AUTOSAR XML (schema 4-2-2)
package /STELLANTIS/EPT/ASWCs
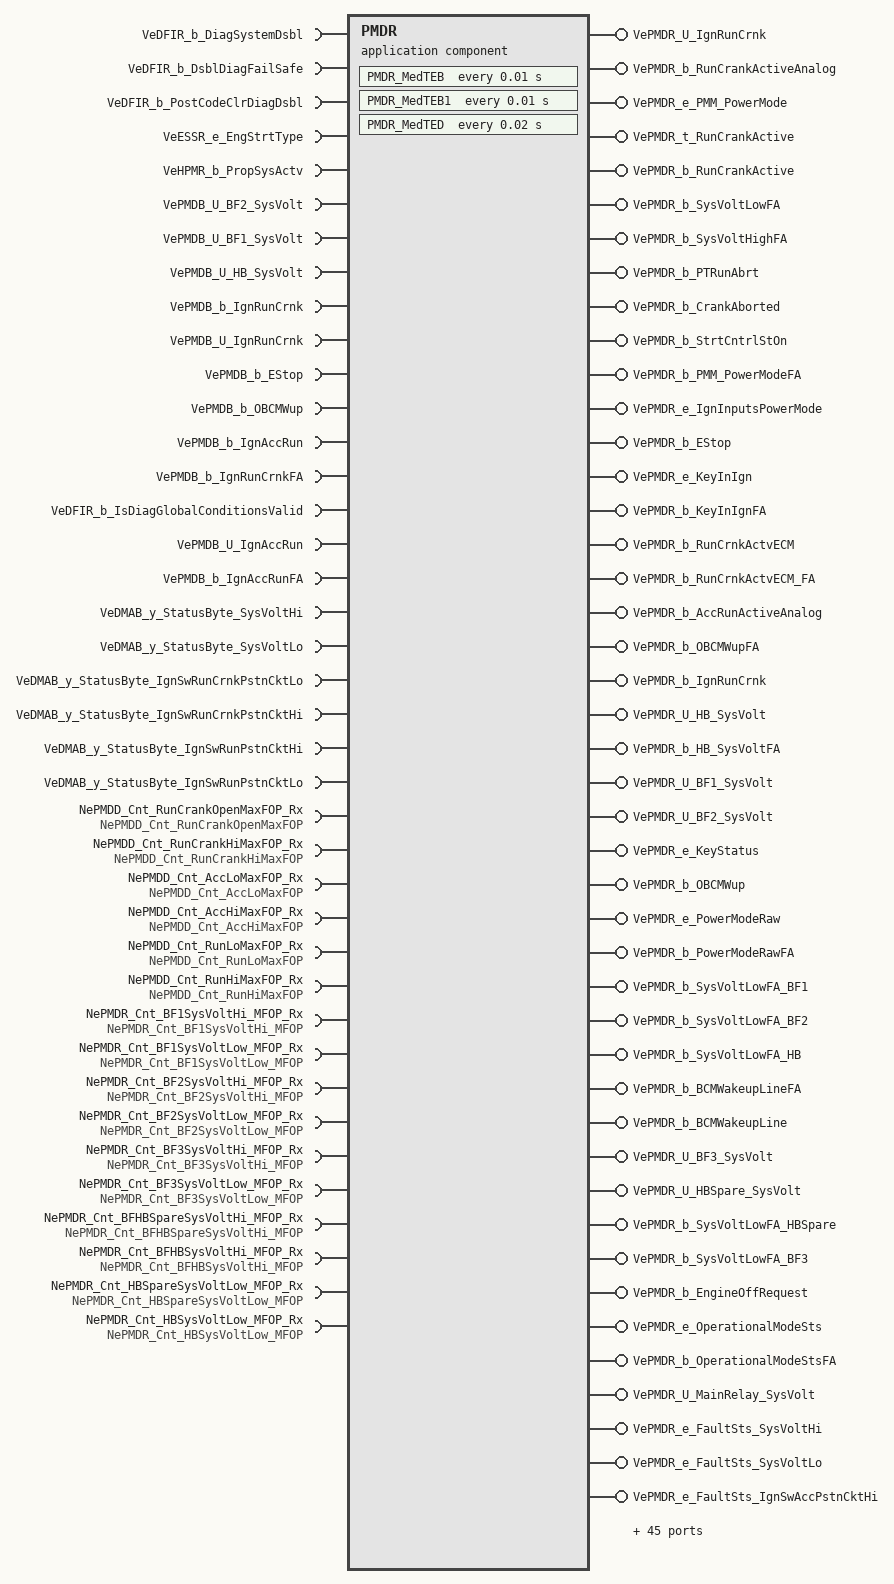
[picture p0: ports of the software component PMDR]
  application sw component type PMDR
    23 x require port:
      VeDFIR_b_DiagSystemDsbl: nonqueued-receiver-com-spec{data-element=Value, init-value=0}, required-interface=VeDFIR_b_DiagSystemDsbl
      VeDFIR_b_DsblDiagFailSafe: variation-point={short-label=vpVeDFIR_b_DsblDiagFailSafe, sw-syscond=1}, nonqueued-receiver-com-spec{data-element=Value, init-value=0}, required-interface=VeDFIR_b_DsblDiagFailSafe
      VeDFIR_b_PostCodeClrDiagDsbl: variation-point={short-label=vpVeDFIR_b_PostCodeClrDiagDsbl, sw-syscond=1}, nonqueued-receiver-com-spec{data-element=Value, init-value=0}, required-interface=VeDFIR_b_PostCodeClrDiagDsbl
      VeESSR_e_EngStrtType: nonqueued-receiver-com-spec{data-element=Value, init-value=CeESSR_e_NoStrt}, required-interface=VeESSR_e_EngStrtType
      VeHPMR_b_PropSysActv: variation-point={short-label=vpVeHPMR_b_PropSysActv, sw-syscond=1}, nonqueued-receiver-com-spec{data-element=Value, init-value=0}, required-interface=VeHPMR_b_PropSysActv
      VePMDB_U_BF2_SysVolt: nonqueued-receiver-com-spec{data-element=Value, init-value=0}, required-interface=VePMDB_U_BF2_SysVolt
      VePMDB_U_BF1_SysVolt: nonqueued-receiver-com-spec{data-element=Value, init-value=0}, required-interface=VePMDB_U_BF1_SysVolt
      VePMDB_U_HB_SysVolt: nonqueued-receiver-com-spec{data-element=Value, init-value=0}, required-interface=VePMDB_U_HB_SysVolt
      VePMDB_b_IgnRunCrnk: nonqueued-receiver-com-spec{data-element=Value, init-value=0}, required-interface=VePMDB_b_IgnRunCrnk
      VePMDB_U_IgnRunCrnk: nonqueued-receiver-com-spec{data-element=Value, init-value=0}, required-interface=VePMDB_U_IgnRunCrnk
      VePMDB_b_EStop: nonqueued-receiver-com-spec{data-element=Value, init-value=0}, required-interface=VePMDB_b_EStop
      VePMDB_b_OBCMWup: nonqueued-receiver-com-spec{data-element=Value, init-value=0}, required-interface=VePMDB_b_OBCMWup
      VePMDB_b_IgnAccRun: nonqueued-receiver-com-spec{data-element=Value, init-value=0}, required-interface=VePMDB_b_IgnAccRun
      VePMDB_b_IgnRunCrnkFA: nonqueued-receiver-com-spec{data-element=Value, init-value=0}, required-interface=VePMDB_b_IgnRunCrnkFA
      VeDFIR_b_IsDiagGlobalConditionsValid: variation-point={short-label=vpVeDFIR_b_IsDiagGlobalConditionsValid, sw-syscond=1}, nonqueued-receiver-com-spec{data-element=Value, init-value=0}, required-interface=VeDFIR_b_IsDiagGlobalConditionsValid
      VePMDB_U_IgnAccRun: nonqueued-receiver-com-spec{data-element=Value, init-value=0}, required-interface=VePMDB_U_IgnAccRun
      VePMDB_b_IgnAccRunFA: nonqueued-receiver-com-spec{data-element=Value, init-value=0}, required-interface=VePMDB_b_IgnAccRunFA
      VeDMAB_y_StatusByte_SysVoltHi: variation-point={short-label=vpVeDMAB_y_StatusByte_SysVoltHi, sw-syscond=1}, nonqueued-receiver-com-spec{data-element=Value, init-value=0}, required-interface=VeDMAB_y_StatusByte_SysVoltHi
      VeDMAB_y_StatusByte_SysVoltLo: variation-point={short-label=vpVeDMAB_y_StatusByte_SysVoltLo, sw-syscond=1}, nonqueued-receiver-com-spec{data-element=Value, init-value=0}, required-interface=VeDMAB_y_StatusByte_SysVoltLo
      VeDMAB_y_StatusByte_IgnSwRunCrnkPstnCktLo: variation-point={short-label=vpVeDMAB_y_StatusByte_IgnSwRunCrnkPstnCktLo, sw-syscond=1}, nonqueued-receiver-com-spec{data-element=Value, init-value=0}, required-interface=VeDMAB_y_StatusByte_IgnSwRunCrnkPstnCktLo
      VeDMAB_y_StatusByte_IgnSwRunCrnkPstnCktHi: variation-point={short-label=vpVeDMAB_y_StatusByte_IgnSwRunCrnkPstnCktHi, sw-syscond=1}, nonqueued-receiver-com-spec{data-element=Value, init-value=0}, required-interface=VeDMAB_y_StatusByte_IgnSwRunCrnkPstnCktHi
      VeDMAB_y_StatusByte_IgnSwRunPstnCktHi: variation-point={short-label=vpVeDMAB_y_StatusByte_IgnSwRunPstnCktHi, sw-syscond=1}, nonqueued-receiver-com-spec{data-element=Value, init-value=0}, required-interface=VeDMAB_y_StatusByte_IgnSwRunPstnCktHi
      VeDMAB_y_StatusByte_IgnSwRunPstnCktLo: variation-point={short-label=vpVeDMAB_y_StatusByte_IgnSwRunPstnCktLo, sw-syscond=1}, nonqueued-receiver-com-spec{data-element=Value, init-value=0}, required-interface=VeDMAB_y_StatusByte_IgnSwRunPstnCktLo
    73 x provide port:
      VePMDR_U_IgnRunCrnk: nonqueued-sender-com-spec{data-element=Value, init-value=0}, provided-interface=VePMDR_U_IgnRunCrnk
      VePMDR_b_RunCrankActiveAnalog: nonqueued-sender-com-spec{data-element=Value, init-value=0}, provided-interface=VePMDR_b_RunCrankActiveAnalog
      VePMDR_e_PMM_PowerMode: nonqueued-sender-com-spec{data-element=Value, init-value=CePMDR_e_PowerMode_Off}, provided-interface=VePMDR_e_PMM_PowerMode
      VePMDR_t_RunCrankActive: nonqueued-sender-com-spec{data-element=Value, init-value=0}, provided-interface=VePMDR_t_RunCrankActive
      VePMDR_b_RunCrankActive: nonqueued-sender-com-spec{data-element=Value, init-value=0}, provided-interface=VePMDR_b_RunCrankActive
      VePMDR_b_SysVoltLowFA: nonqueued-sender-com-spec{data-element=Value, init-value=0}, provided-interface=VePMDR_b_SysVoltLowFA
      VePMDR_b_SysVoltHighFA: nonqueued-sender-com-spec{data-element=Value, init-value=0}, provided-interface=VePMDR_b_SysVoltHighFA
      VePMDR_b_PTRunAbrt: nonqueued-sender-com-spec{data-element=Value, init-value=0}, provided-interface=VePMDR_b_PTRunAbrt
      VePMDR_b_CrankAborted: nonqueued-sender-com-spec{data-element=Value, init-value=0}, provided-interface=VePMDR_b_CrankAborted
      VePMDR_b_StrtCntrlStOn: nonqueued-sender-com-spec{data-element=Value, init-value=0}, provided-interface=VePMDR_b_StrtCntrlStOn
      VePMDR_b_PMM_PowerModeFA: nonqueued-sender-com-spec{data-element=Value, init-value=0}, provided-interface=VePMDR_b_PMM_PowerModeFA
      VePMDR_e_IgnInputsPowerMode: nonqueued-sender-com-spec{data-element=Value, init-value=CePMDR_e_PowerMode_Off}, provided-interface=VePMDR_e_IgnInputsPowerMode
      VePMDR_b_EStop: nonqueued-sender-com-spec{data-element=Value, init-value=0}, provided-interface=VePMDR_b_EStop
      VePMDR_e_KeyInIgn: nonqueued-sender-com-spec{data-element=Value, init-value=CePMDR_e_KeyInIgn_DEFAULT}, provided-interface=VePMDR_e_KeyInIgn
      VePMDR_b_KeyInIgnFA: nonqueued-sender-com-spec{data-element=Value, init-value=0}, provided-interface=VePMDR_b_KeyInIgnFA
      VePMDR_b_RunCrnkActvECM: nonqueued-sender-com-spec{data-element=Value, init-value=0}, provided-interface=VePMDR_b_RunCrnkActvECM
      VePMDR_b_RunCrnkActvECM_FA: nonqueued-sender-com-spec{data-element=Value, init-value=0}, provided-interface=VePMDR_b_RunCrnkActvECM_FA
      VePMDR_b_AccRunActiveAnalog: nonqueued-sender-com-spec{data-element=Value, init-value=0}, provided-interface=VePMDR_b_AccRunActiveAnalog
      VePMDR_b_OBCMWupFA: nonqueued-sender-com-spec{data-element=Value, init-value=0}, provided-interface=VePMDR_b_OBCMWupFA
      VePMDR_b_IgnRunCrnk: nonqueued-sender-com-spec{data-element=Value, init-value=0}, provided-interface=VePMDR_b_IgnRunCrnk
      VePMDR_U_HB_SysVolt: nonqueued-sender-com-spec{data-element=Value, init-value=0}, provided-interface=VePMDR_U_HB_SysVolt
      VePMDR_b_HB_SysVoltFA: nonqueued-sender-com-spec{data-element=Value, init-value=0}, provided-interface=VePMDR_b_HB_SysVoltFA
      VePMDR_U_BF1_SysVolt: nonqueued-sender-com-spec{data-element=Value, init-value=0}, provided-interface=VePMDR_U_BF1_SysVolt
      VePMDR_U_BF2_SysVolt: nonqueued-sender-com-spec{data-element=Value, init-value=0}, provided-interface=VePMDR_U_BF2_SysVolt
      VePMDR_e_KeyStatus: nonqueued-sender-com-spec{data-element=Value, init-value=CePMDR_e_KeySt_Off}, provided-interface=VePMDR_e_KeyStatus
      VePMDR_b_OBCMWup: nonqueued-sender-com-spec{data-element=Value, init-value=0}, provided-interface=VePMDR_b_OBCMWup
      VePMDR_e_PowerModeRaw: nonqueued-sender-com-spec{data-element=Value, init-value=CePMDR_e_PowerMode_Off}, provided-interface=VePMDR_e_PowerModeRaw
      VePMDR_b_PowerModeRawFA: nonqueued-sender-com-spec{data-element=Value, init-value=0}, provided-interface=VePMDR_b_PowerModeRawFA
      VePMDR_b_SysVoltLowFA_BF1: nonqueued-sender-com-spec{data-element=Value, init-value=0}, provided-interface=VePMDR_b_SysVoltLowFA_BF1
      VePMDR_b_SysVoltLowFA_BF2: nonqueued-sender-com-spec{data-element=Value, init-value=0}, provided-interface=VePMDR_b_SysVoltLowFA_BF2
      VePMDR_b_SysVoltLowFA_HB: nonqueued-sender-com-spec{data-element=Value, init-value=0}, provided-interface=VePMDR_b_SysVoltLowFA_HB
      VePMDR_b_BCMWakeupLineFA: nonqueued-sender-com-spec{data-element=Value, init-value=0}, provided-interface=VePMDR_b_BCMWakeupLineFA
      VePMDR_b_BCMWakeupLine: nonqueued-sender-com-spec{data-element=Value, init-value=0}, provided-interface=VePMDR_b_BCMWakeupLine
      VePMDR_U_BF3_SysVolt: nonqueued-sender-com-spec{data-element=Value, init-value=0}, provided-interface=VePMDR_U_BF3_SysVolt
      VePMDR_U_HBSpare_SysVolt: nonqueued-sender-com-spec{data-element=Value, init-value=0}, provided-interface=VePMDR_U_HBSpare_SysVolt
      VePMDR_b_SysVoltLowFA_HBSpare: nonqueued-sender-com-spec{data-element=Value, init-value=0}, provided-interface=VePMDR_b_SysVoltLowFA_HBSpare
      VePMDR_b_SysVoltLowFA_BF3: nonqueued-sender-com-spec{data-element=Value, init-value=0}, provided-interface=VePMDR_b_SysVoltLowFA_BF3
      VePMDR_b_EngineOffRequest: nonqueued-sender-com-spec{data-element=Value, init-value=0}, provided-interface=VePMDR_b_EngineOffRequest
      VePMDR_e_OperationalModeSts: nonqueued-sender-com-spec{data-element=Value, init-value=CePMDR_e_Init}, provided-interface=VePMDR_e_OperationalModeSts
      VePMDR_b_OperationalModeStsFA: nonqueued-sender-com-spec{data-element=Value, init-value=0}, provided-interface=VePMDR_b_OperationalModeStsFA
      VePMDR_U_MainRelay_SysVolt: nonqueued-sender-com-spec{data-element=Value, init-value=0}, provided-interface=VePMDR_U_MainRelay_SysVolt
      VePMDR_e_FaultSts_SysVoltHi: nonqueued-sender-com-spec{data-element=Value, init-value=CeDFIB_e_Init}, provided-interface=VePMDR_e_FaultSts_SysVoltHi
      VePMDR_e_FaultSts_SysVoltLo: nonqueued-sender-com-spec{data-element=Value, init-value=CeDFIB_e_Init}, provided-interface=VePMDR_e_FaultSts_SysVoltLo
      VePMDR_e_FaultSts_IgnSwAccPstnCktHi: nonqueued-sender-com-spec{data-element=Value, init-value=CeDFIB_e_Init}, provided-interface=VePMDR_e_FaultSts_IgnSwAccPstnCktHi
      VePMDR_e_FaultSts_IgnSwAccPstnCktLo: nonqueued-sender-com-spec{data-element=Value, init-value=CeDFIB_e_Init}, provided-interface=VePMDR_e_FaultSts_IgnSwAccPstnCktLo
      VePMDR_e_FaultSts_IgnSwRunCrnkPstnCktLo: nonqueued-sender-com-spec{data-element=Value, init-value=CeDFIB_e_Init}, provided-interface=VePMDR_e_FaultSts_IgnSwRunCrnkPstnCktLo
      VePMDR_e_FaultSts_IgnSwRunCrnkPstnCktHi: nonqueued-sender-com-spec{data-element=Value, init-value=CeDFIB_e_Init}, provided-interface=VePMDR_e_FaultSts_IgnSwRunCrnkPstnCktHi
      VePMDR_e_FaultSts_IgnSwRunPstnCktHi: nonqueued-sender-com-spec{data-element=Value, init-value=CeDFIB_e_Init}, provided-interface=VePMDR_e_FaultSts_IgnSwRunPstnCktHi
      VePMDR_e_FaultSts_IgnSwRunPstnCktLo: nonqueued-sender-com-spec{data-element=Value, init-value=CeDFIB_e_Init}, provided-interface=VePMDR_e_FaultSts_IgnSwRunPstnCktLo
      FsftPMDR_b_EngOffRq_C: server-com-spec=FsftPMDR_b_EngOffRq_C, provided-interface=FsftPMDR_b_EngOffRq_C
      FsftPMDR_b_EngOffRq_C2: server-com-spec=FsftPMDR_b_EngOffRq_C2, provided-interface=FsftPMDR_b_EngOffRq_C2
      FsftPMDR_b_OperationalModeSts: server-com-spec=FsftPMDR_b_OperationalModeSts, provided-interface=FsftPMDR_b_OperationalModeSts
      FsftPMDR_b_PAD_Actv: server-com-spec=FsftPMDR_b_PAD_Actv, provided-interface=FsftPMDR_b_PAD_Actv
      FsftPMDR_b_RunCrnkActvECM: server-com-spec=FsftPMDR_b_RunCrnkActvECM, provided-interface=FsftPMDR_b_RunCrnkActvECM
      FsftPMDR_b_StrtCntrlStOn: server-com-spec=FsftPMDR_b_StrtCntrlStOn, provided-interface=FsftPMDR_b_StrtCntrlStOn
      FsftPMDR_e_KeyInIgn: server-com-spec=FsftPMDR_e_KeyInIgn, provided-interface=FsftPMDR_e_KeyInIgn
      FsftPMDR_e_PowerModeRaw: server-com-spec=FsftPMDR_e_PowerModeRaw, provided-interface=FsftPMDR_e_PowerModeRaw
      FsftPMDR_e_Tonale_PowerModeRaw: server-com-spec=FsftPMDR_e_Tonale_PowerModeRaw, provided-interface=FsftPMDR_e_Tonale_PowerModeRaw
      PokePMDR_U_BF3_SysVolt: server-com-spec{operation=PokePMDR_U_BF3_SysVolt, queue-length=1}, provided-interface=PokePMDR_U_BF3_SysVolt
      PokePMDR_U_HBSpare_SysVolt: server-com-spec{operation=PokePMDR_U_HBSpare_SysVolt, queue-length=1}, provided-interface=PokePMDR_U_HBSpare_SysVolt
      PokePMDR_U_MainRelay_SysVolt: server-com-spec{operation=PokePMDR_U_MainRelay_SysVolt, queue-length=1}, provided-interface=PokePMDR_U_MainRelay_SysVolt
      PokePMDR_b_BCMWup: server-com-spec{operation=PokePMDR_b_BCMWup, queue-length=1}, provided-interface=PokePMDR_b_BCMWup
      PokePMDR_b_CrankAborted: server-com-spec{operation=PokePMDR_b_CrankAborted, queue-length=1}, provided-interface=PokePMDR_b_CrankAborted
      PokePMDR_b_EngOffRq_C: server-com-spec{operation=PokePMDR_b_EngOffRq_C, queue-length=1}, provided-interface=PokePMDR_b_EngOffRq_C
      PokePMDR_b_EngOffRq_C2: server-com-spec{operation=PokePMDR_b_EngOffRq_C2, queue-length=1}, provided-interface=PokePMDR_b_EngOffRq_C2
      PokePMDR_b_PAD_Actv: server-com-spec{operation=PokePMDR_b_PAD_Actv, queue-length=1}, provided-interface=PokePMDR_b_PAD_Actv
      PokePMDR_b_PTRunAbrt: server-com-spec{operation=PokePMDR_b_PTRunAbrt, queue-length=1}, provided-interface=PokePMDR_b_PTRunAbrt
      PokePMDR_b_RunCrnkActvECM: server-com-spec{operation=PokePMDR_b_RunCrnkActvECM, queue-length=1}, provided-interface=PokePMDR_b_RunCrnkActvECM
      PokePMDR_b_StrtCntrlStOn: server-com-spec{operation=PokePMDR_b_StrtCntrlStOn, queue-length=1}, provided-interface=PokePMDR_b_StrtCntrlStOn
      PokePMDR_e_KeyInIgn: server-com-spec{operation=PokePMDR_e_KeyInIgn, queue-length=1}, provided-interface=PokePMDR_e_KeyInIgn
      PokePMDR_e_OperationalModeSts: server-com-spec{operation=PokePMDR_e_OperationalModeSts, queue-length=1}, provided-interface=PokePMDR_e_OperationalModeSts
      PokePMDR_e_PowerModeRaw: server-com-spec{operation=PokePMDR_e_PowerModeRaw, queue-length=1}, provided-interface=PokePMDR_e_PowerModeRaw
      PokePMDR_e_Tonale_PowerModeRaw: server-com-spec{operation=PokePMDR_e_Tonale_PowerModeRaw, queue-length=1}, provided-interface=PokePMDR_e_Tonale_PowerModeRaw
    16 x require port:
      NePMDD_Cnt_RunCrankOpenMaxFOP_Rx: nv-require-com-spec{init-value=0, variable=NePMDD_Cnt_RunCrankOpenMaxFOP}, required-interface=NePMDD_Cnt_RunCrankOpenMaxFOP
      NePMDD_Cnt_RunCrankHiMaxFOP_Rx: nv-require-com-spec{init-value=0, variable=NePMDD_Cnt_RunCrankHiMaxFOP}, required-interface=NePMDD_Cnt_RunCrankHiMaxFOP
      NePMDD_Cnt_AccLoMaxFOP_Rx: nv-require-com-spec{init-value=0, variable=NePMDD_Cnt_AccLoMaxFOP}, required-interface=NePMDD_Cnt_AccLoMaxFOP
      NePMDD_Cnt_AccHiMaxFOP_Rx: nv-require-com-spec{init-value=0, variable=NePMDD_Cnt_AccHiMaxFOP}, required-interface=NePMDD_Cnt_AccHiMaxFOP
      NePMDD_Cnt_RunLoMaxFOP_Rx: nv-require-com-spec{init-value=0, variable=NePMDD_Cnt_RunLoMaxFOP}, required-interface=NePMDD_Cnt_RunLoMaxFOP
      NePMDD_Cnt_RunHiMaxFOP_Rx: nv-require-com-spec{init-value=0, variable=NePMDD_Cnt_RunHiMaxFOP}, required-interface=NePMDD_Cnt_RunHiMaxFOP
      NePMDR_Cnt_BF1SysVoltHi_MFOP_Rx: nv-require-com-spec{init-value=0, variable=NePMDR_Cnt_BF1SysVoltHi_MFOP}, required-interface=NePMDR_Cnt_BF1SysVoltHi_MFOP
      NePMDR_Cnt_BF1SysVoltLow_MFOP_Rx: nv-require-com-spec{init-value=0, variable=NePMDR_Cnt_BF1SysVoltLow_MFOP}, required-interface=NePMDR_Cnt_BF1SysVoltLow_MFOP
      NePMDR_Cnt_BF2SysVoltHi_MFOP_Rx: nv-require-com-spec{init-value=0, variable=NePMDR_Cnt_BF2SysVoltHi_MFOP}, required-interface=NePMDR_Cnt_BF2SysVoltHi_MFOP
      NePMDR_Cnt_BF2SysVoltLow_MFOP_Rx: nv-require-com-spec{init-value=0, variable=NePMDR_Cnt_BF2SysVoltLow_MFOP}, required-interface=NePMDR_Cnt_BF2SysVoltLow_MFOP
      NePMDR_Cnt_BF3SysVoltHi_MFOP_Rx: nv-require-com-spec{init-value=0, variable=NePMDR_Cnt_BF3SysVoltHi_MFOP}, required-interface=NePMDR_Cnt_BF3SysVoltHi_MFOP
      NePMDR_Cnt_BF3SysVoltLow_MFOP_Rx: nv-require-com-spec{init-value=0, variable=NePMDR_Cnt_BF3SysVoltLow_MFOP}, required-interface=NePMDR_Cnt_BF3SysVoltLow_MFOP
      NePMDR_Cnt_BFHBSpareSysVoltHi_MFOP_Rx: nv-require-com-spec{init-value=0, variable=NePMDR_Cnt_BFHBSpareSysVoltHi_MFOP}, required-interface=NePMDR_Cnt_BFHBSpareSysVoltHi_MFOP
      NePMDR_Cnt_BFHBSysVoltHi_MFOP_Rx: nv-require-com-spec{init-value=0, variable=NePMDR_Cnt_BFHBSysVoltHi_MFOP}, required-interface=NePMDR_Cnt_BFHBSysVoltHi_MFOP
      NePMDR_Cnt_HBSpareSysVoltLow_MFOP_Rx: nv-require-com-spec{init-value=0, variable=NePMDR_Cnt_HBSpareSysVoltLow_MFOP}, required-interface=NePMDR_Cnt_HBSpareSysVoltLow_MFOP
      NePMDR_Cnt_HBSysVoltLow_MFOP_Rx: nv-require-com-spec{init-value=0, variable=NePMDR_Cnt_HBSysVoltLow_MFOP}, required-interface=NePMDR_Cnt_HBSysVoltLow_MFOP
    16 x provide port:
      NePMDD_Cnt_RunCrankOpenMaxFOP: nv-provide-com-spec{ram-block-init-value=0, variable=NePMDD_Cnt_RunCrankOpenMaxFOP}, provided-interface=NePMDD_Cnt_RunCrankOpenMaxFOP
      NePMDD_Cnt_RunCrankHiMaxFOP: nv-provide-com-spec{ram-block-init-value=0, variable=NePMDD_Cnt_RunCrankHiMaxFOP}, provided-interface=NePMDD_Cnt_RunCrankHiMaxFOP
      NePMDD_Cnt_AccLoMaxFOP: nv-provide-com-spec{ram-block-init-value=0, variable=NePMDD_Cnt_AccLoMaxFOP}, provided-interface=NePMDD_Cnt_AccLoMaxFOP
      NePMDD_Cnt_AccHiMaxFOP: nv-provide-com-spec{ram-block-init-value=0, variable=NePMDD_Cnt_AccHiMaxFOP}, provided-interface=NePMDD_Cnt_AccHiMaxFOP
      NePMDD_Cnt_RunLoMaxFOP: nv-provide-com-spec{ram-block-init-value=0, variable=NePMDD_Cnt_RunLoMaxFOP}, provided-interface=NePMDD_Cnt_RunLoMaxFOP
      NePMDD_Cnt_RunHiMaxFOP: nv-provide-com-spec{ram-block-init-value=0, variable=NePMDD_Cnt_RunHiMaxFOP}, provided-interface=NePMDD_Cnt_RunHiMaxFOP
      NePMDR_Cnt_BF1SysVoltHi_MFOP: nv-provide-com-spec{ram-block-init-value=0, variable=NePMDR_Cnt_BF1SysVoltHi_MFOP}, provided-interface=NePMDR_Cnt_BF1SysVoltHi_MFOP
      NePMDR_Cnt_BF1SysVoltLow_MFOP: nv-provide-com-spec{ram-block-init-value=0, variable=NePMDR_Cnt_BF1SysVoltLow_MFOP}, provided-interface=NePMDR_Cnt_BF1SysVoltLow_MFOP
      NePMDR_Cnt_BF2SysVoltHi_MFOP: nv-provide-com-spec{ram-block-init-value=0, variable=NePMDR_Cnt_BF2SysVoltHi_MFOP}, provided-interface=NePMDR_Cnt_BF2SysVoltHi_MFOP
      NePMDR_Cnt_BF2SysVoltLow_MFOP: nv-provide-com-spec{ram-block-init-value=0, variable=NePMDR_Cnt_BF2SysVoltLow_MFOP}, provided-interface=NePMDR_Cnt_BF2SysVoltLow_MFOP
      NePMDR_Cnt_BF3SysVoltHi_MFOP: nv-provide-com-spec{ram-block-init-value=0, variable=NePMDR_Cnt_BF3SysVoltHi_MFOP}, provided-interface=NePMDR_Cnt_BF3SysVoltHi_MFOP
      NePMDR_Cnt_BF3SysVoltLow_MFOP: nv-provide-com-spec{ram-block-init-value=0, variable=NePMDR_Cnt_BF3SysVoltLow_MFOP}, provided-interface=NePMDR_Cnt_BF3SysVoltLow_MFOP
      NePMDR_Cnt_BFHBSpareSysVoltHi_MFOP: nv-provide-com-spec{ram-block-init-value=0, variable=NePMDR_Cnt_BFHBSpareSysVoltHi_MFOP}, provided-interface=NePMDR_Cnt_BFHBSpareSysVoltHi_MFOP
      NePMDR_Cnt_BFHBSysVoltHi_MFOP: nv-provide-com-spec{ram-block-init-value=0, variable=NePMDR_Cnt_BFHBSysVoltHi_MFOP}, provided-interface=NePMDR_Cnt_BFHBSysVoltHi_MFOP
      NePMDR_Cnt_HBSpareSysVoltLow_MFOP: nv-provide-com-spec{ram-block-init-value=0, variable=NePMDR_Cnt_HBSpareSysVoltLow_MFOP}, provided-interface=NePMDR_Cnt_HBSpareSysVoltLow_MFOP
      NePMDR_Cnt_HBSysVoltLow_MFOP: nv-provide-com-spec{ram-block-init-value=0, variable=NePMDR_Cnt_HBSysVoltLow_MFOP}, provided-interface=NePMDR_Cnt_HBSysVoltLow_MFOP
    behavior IB_PMDR: data-type-mapping=msADTtoIDTMapping, handle-termination-and-restart=NO-SUPPORT, included-data-type-set=data-type=[TePMDR_e_AccRunSrc, TePMDR_e_PMM_PowerModeSrc, TePMDR_e_RunCrankSrc]
      timing event Event_MedTEB: start-on-event=PMDR_MedTEB, period=0.01
      timing event Event_MedTEB1: start-on-event=PMDR_MedTEB1, period=0.01
      timing event Event_MedTED: start-on-event=PMDR_MedTED, period=0.02
      24 x operation invoked event:
        Event_FsftPMDR_b_EngOffRq_C: start-on-event=FsftPMDR_b_EngOffRq_C, operation=FsftPMDR_b_EngOffRq_C.FsftPMDR_b_EngOffRq_C
        Event_FsftPMDR_b_EngOffRq_C2: start-on-event=FsftPMDR_b_EngOffRq_C2, operation=FsftPMDR_b_EngOffRq_C2.FsftPMDR_b_EngOffRq_C2
        Event_FsftPMDR_b_OperationalModeSts: start-on-event=FsftPMDR_b_OperationalModeSts, operation=FsftPMDR_b_OperationalModeSts.FsftPMDR_b_OperationalModeSts
        Event_FsftPMDR_b_PAD_Actv: start-on-event=FsftPMDR_b_PAD_Actv, operation=FsftPMDR_b_PAD_Actv.FsftPMDR_b_PAD_Actv
        Event_FsftPMDR_b_RunCrnkActvECM: start-on-event=FsftPMDR_b_RunCrnkActvECM, operation=FsftPMDR_b_RunCrnkActvECM.FsftPMDR_b_RunCrnkActvECM
        Event_FsftPMDR_b_StrtCntrlStOn: start-on-event=FsftPMDR_b_StrtCntrlStOn, operation=FsftPMDR_b_StrtCntrlStOn.FsftPMDR_b_StrtCntrlStOn
        Event_FsftPMDR_e_KeyInIgn: start-on-event=FsftPMDR_e_KeyInIgn, operation=FsftPMDR_e_KeyInIgn.FsftPMDR_e_KeyInIgn
        Event_FsftPMDR_e_PowerModeRaw: start-on-event=FsftPMDR_e_PowerModeRaw, operation=FsftPMDR_e_PowerModeRaw.FsftPMDR_e_PowerModeRaw
        Event_FsftPMDR_e_Tonale_PowerModeRaw: start-on-event=FsftPMDR_e_Tonale_PowerModeRaw, operation=FsftPMDR_e_Tonale_PowerModeRaw.FsftPMDR_e_Tonale_PowerModeRaw
        Event_PokePMDR_U_BF3_SysVolt: start-on-event=PokePMDR_U_BF3_SysVolt, operation=PokePMDR_U_BF3_SysVolt.PokePMDR_U_BF3_SysVolt
        Event_PokePMDR_U_HBSpare_SysVolt: start-on-event=PokePMDR_U_HBSpare_SysVolt, operation=PokePMDR_U_HBSpare_SysVolt.PokePMDR_U_HBSpare_SysVolt
        Event_PokePMDR_U_MainRelay_SysVolt: start-on-event=PokePMDR_U_MainRelay_SysVolt, operation=PokePMDR_U_MainRelay_SysVolt.PokePMDR_U_MainRelay_SysVolt
        Event_PokePMDR_b_BCMWup: start-on-event=PokePMDR_b_BCMWup, operation=PokePMDR_b_BCMWup.PokePMDR_b_BCMWup
        Event_PokePMDR_b_CrankAborted: start-on-event=PokePMDR_b_CrankAborted, operation=PokePMDR_b_CrankAborted.PokePMDR_b_CrankAborted
        Event_PokePMDR_b_EngOffRq_C: start-on-event=PokePMDR_b_EngOffRq_C, operation=PokePMDR_b_EngOffRq_C.PokePMDR_b_EngOffRq_C
        Event_PokePMDR_b_EngOffRq_C2: start-on-event=PokePMDR_b_EngOffRq_C2, operation=PokePMDR_b_EngOffRq_C2.PokePMDR_b_EngOffRq_C2
        Event_PokePMDR_b_PAD_Actv: start-on-event=PokePMDR_b_PAD_Actv, operation=PokePMDR_b_PAD_Actv.PokePMDR_b_PAD_Actv
        Event_PokePMDR_b_PTRunAbrt: start-on-event=PokePMDR_b_PTRunAbrt, operation=PokePMDR_b_PTRunAbrt.PokePMDR_b_PTRunAbrt
        Event_PokePMDR_b_RunCrnkActvECM: start-on-event=PokePMDR_b_RunCrnkActvECM, operation=PokePMDR_b_RunCrnkActvECM.PokePMDR_b_RunCrnkActvECM
        Event_PokePMDR_b_StrtCntrlStOn: start-on-event=PokePMDR_b_StrtCntrlStOn, operation=PokePMDR_b_StrtCntrlStOn.PokePMDR_b_StrtCntrlStOn
        Event_PokePMDR_e_KeyInIgn: start-on-event=PokePMDR_e_KeyInIgn, operation=PokePMDR_e_KeyInIgn.PokePMDR_e_KeyInIgn
        Event_PokePMDR_e_OperationalModeSts: start-on-event=PokePMDR_e_OperationalModeSts, operation=PokePMDR_e_OperationalModeSts.PokePMDR_e_OperationalModeSts
        Event_PokePMDR_e_PowerModeRaw: start-on-event=PokePMDR_e_PowerModeRaw, operation=PokePMDR_e_PowerModeRaw.PokePMDR_e_PowerModeRaw
        Event_PokePMDR_e_Tonale_PowerModeRaw: start-on-event=PokePMDR_e_Tonale_PowerModeRaw, operation=PokePMDR_e_Tonale_PowerModeRaw.PokePMDR_e_Tonale_PowerModeRaw
      init event Event_PMDR_ac_Init: start-on-event=PMDR_ac_Init
      init event Event_PwrOn: start-on-event=PMDR_PwrOn
      init event Event_PwrOff: start-on-event=PMDR_PwrOff
      explicit-inter-runnable-variables:
        22 x data, all with category=VALUE, sw-calibration-access=READ-ONLY:
          VePMDR_e_PowerModeRaw_write_IRV: type=TePMDR_e_PowerMode, init-value=CePMDR_e_PowerMode_Off
          VePMDR_e_Tonale_PowerModeRaw_write_IRV: type=TePMDR_e_PowerMode, init-value=CePMDR_e_PowerMode_Off
          VePMDR_b_PowerModeRawFA_write_IRV: type=Boolean, init-value=0
          VePMDR_b_Tonale_PowerModeRawFA_write_IRV: type=Boolean, init-value=0
          VePMDR_b_RunCrnkActvECM_write_IRV: type=Boolean, init-value=0
          VePMDR_b_RunCrnkActvECMFA_write_IRV: type=Boolean, init-value=0
          VePMDR_b_StrtCntrlStOn_ECM_write_IRV: type=Boolean, init-value=0
          VePMDR_b_EngOffRq_CFA_write_IRV: type=Boolean, init-value=0
          VePMDR_b_EngOffRq_C2FA_write_IRV: type=Boolean, init-value=0
          VePMDR_b_EngOffReq_C_Init_write_IRV: type=Boolean, init-value=0
          VePMDR_b_EngOffReq_C2_Init_write_IRV: type=Boolean, init-value=0
          VePMDR_b_RunCrankActive_write_IRV: type=Boolean, init-value=0
          VePMDR_b_RunCrankActiveAnalog_write_IRV: type=Boolean, init-value=0
          VePMDR_e_PMM_PowerMode_write_IRV: type=TePMDR_e_PowerMode, init-value=CePMDR_e_PowerMode_Off
          VePMDR_b_PMM_PowerModeFA_write_IRV: type=Boolean, init-value=0
          VePMDI_e_PowerModeRaw_write_IRV: type=TePMDR_e_PowerMode, init-value=CePMDR_e_PowerMode_Off
          VePMDR_b_PowerModeRawFA_write1_IRV: type=Boolean, init-value=0
          VePMDR_b_AccRunActiveAnalog_write_IRV: type=Boolean, init-value=0
          VePMDR_b_PAD_Actv_Init_write_IRV: type=Boolean, init-value=0
          VePMDR_b_PAD_ActvFA_write_IRV: type=Boolean, init-value=0
          VePMDR_U_HBSpare_SysVolt_write_IRV: type=Float, init-value=0
          VePMDR_U_BF3_SysVolt_write_IRV: type=Float, init-value=0
      30 x runnable:
        PMDR_ac_Init
          data-send-points:
            14 x access:
              OUT_VePMDR_e_PMM_PowerMode_Value: accessed-variable=VePMDR_e_PMM_PowerMode.Value
              OUT_VePMDR_e_IgnInputsPowerMode_Value: accessed-variable=VePMDR_e_IgnInputsPowerMode.Value
              OUT_VePMDR_e_KeyInIgn_Value: accessed-variable=VePMDR_e_KeyInIgn.Value
              OUT_VePMDR_e_KeyStatus_Value: accessed-variable=VePMDR_e_KeyStatus.Value
              OUT_VePMDR_e_PowerModeRaw_Value: accessed-variable=VePMDR_e_PowerModeRaw.Value
              OUT_VePMDR_e_OperationalModeSts_Value: accessed-variable=VePMDR_e_OperationalModeSts.Value
              OUT_VePMDR_e_FaultSts_SysVoltHi_Value: accessed-variable=VePMDR_e_FaultSts_SysVoltHi.Value
              OUT_VePMDR_e_FaultSts_SysVoltLo_Value: accessed-variable=VePMDR_e_FaultSts_SysVoltLo.Value
              OUT_VePMDR_e_FaultSts_IgnSwAccPstnCktHi_Value: accessed-variable=VePMDR_e_FaultSts_IgnSwAccPstnCktHi.Value
              OUT_VePMDR_e_FaultSts_IgnSwAccPstnCktLo_Value: accessed-variable=VePMDR_e_FaultSts_IgnSwAccPstnCktLo.Value
              OUT_VePMDR_e_FaultSts_IgnSwRunCrnkPstnCktLo_Value: accessed-variable=VePMDR_e_FaultSts_IgnSwRunCrnkPstnCktLo.Value
              OUT_VePMDR_e_FaultSts_IgnSwRunCrnkPstnCktHi_Value: accessed-variable=VePMDR_e_FaultSts_IgnSwRunCrnkPstnCktHi.Value
              OUT_VePMDR_e_FaultSts_IgnSwRunPstnCktHi_Value: accessed-variable=VePMDR_e_FaultSts_IgnSwRunPstnCktHi.Value
              OUT_VePMDR_e_FaultSts_IgnSwRunPstnCktLo_Value: accessed-variable=VePMDR_e_FaultSts_IgnSwRunPstnCktLo.Value
        PMDR_PwrOn
          data-receive-point-by-arguments:
            16 x access:
              IN_NePMDD_Cnt_AccHiMaxFOP_Rx_NePMDD_Cnt_AccHiMaxFOP: accessed-variable=NePMDD_Cnt_AccHiMaxFOP_Rx.NePMDD_Cnt_AccHiMaxFOP
              IN_NePMDD_Cnt_AccLoMaxFOP_Rx_NePMDD_Cnt_AccLoMaxFOP: accessed-variable=NePMDD_Cnt_AccLoMaxFOP_Rx.NePMDD_Cnt_AccLoMaxFOP
              IN_NePMDD_Cnt_RunCrankHiMaxFOP_Rx_NePMDD_Cnt_RunCrankHiMaxFOP: accessed-variable=NePMDD_Cnt_RunCrankHiMaxFOP_Rx.NePMDD_Cnt_RunCrankHiMaxFOP
              IN_NePMDD_Cnt_RunCrankOpenMaxFOP_Rx_NePMDD_Cnt_RunCrankOpenMaxFOP: accessed-variable=NePMDD_Cnt_RunCrankOpenMaxFOP_Rx.NePMDD_Cnt_RunCrankOpenMaxFOP
              IN_NePMDD_Cnt_RunHiMaxFOP_Rx_NePMDD_Cnt_RunHiMaxFOP: accessed-variable=NePMDD_Cnt_RunHiMaxFOP_Rx.NePMDD_Cnt_RunHiMaxFOP
              IN_NePMDD_Cnt_RunLoMaxFOP_Rx_NePMDD_Cnt_RunLoMaxFOP: accessed-variable=NePMDD_Cnt_RunLoMaxFOP_Rx.NePMDD_Cnt_RunLoMaxFOP
              IN_NePMDR_Cnt_BF1SysVoltHi_MFOP_Rx_NePMDR_Cnt_BF1SysVoltHi_MFOP: accessed-variable=NePMDR_Cnt_BF1SysVoltHi_MFOP_Rx.NePMDR_Cnt_BF1SysVoltHi_MFOP
              IN_NePMDR_Cnt_BF1SysVoltLow_MFOP_Rx_NePMDR_Cnt_BF1SysVoltLow_MFOP: accessed-variable=NePMDR_Cnt_BF1SysVoltLow_MFOP_Rx.NePMDR_Cnt_BF1SysVoltLow_MFOP
              IN_NePMDR_Cnt_BF2SysVoltHi_MFOP_Rx_NePMDR_Cnt_BF2SysVoltHi_MFOP: accessed-variable=NePMDR_Cnt_BF2SysVoltHi_MFOP_Rx.NePMDR_Cnt_BF2SysVoltHi_MFOP
              IN_NePMDR_Cnt_BF2SysVoltLow_MFOP_Rx_NePMDR_Cnt_BF2SysVoltLow_MFOP: accessed-variable=NePMDR_Cnt_BF2SysVoltLow_MFOP_Rx.NePMDR_Cnt_BF2SysVoltLow_MFOP
              IN_NePMDR_Cnt_BF3SysVoltHi_MFOP_Rx_NePMDR_Cnt_BF3SysVoltHi_MFOP: accessed-variable=NePMDR_Cnt_BF3SysVoltHi_MFOP_Rx.NePMDR_Cnt_BF3SysVoltHi_MFOP
              IN_NePMDR_Cnt_BF3SysVoltLow_MFOP_Rx_NePMDR_Cnt_BF3SysVoltLow_MFOP: accessed-variable=NePMDR_Cnt_BF3SysVoltLow_MFOP_Rx.NePMDR_Cnt_BF3SysVoltLow_MFOP
              IN_NePMDR_Cnt_BFHBSpareSysVoltHi_MFOP_Rx_NePMDR_Cnt_BFHBSpareSysVoltHi_MFOP: accessed-variable=NePMDR_Cnt_BFHBSpareSysVoltHi_MFOP_Rx.NePMDR_Cnt_BFHBSpareSysVoltHi_MFOP
              IN_NePMDR_Cnt_BFHBSysVoltHi_MFOP_Rx_NePMDR_Cnt_BFHBSysVoltHi_MFOP: accessed-variable=NePMDR_Cnt_BFHBSysVoltHi_MFOP_Rx.NePMDR_Cnt_BFHBSysVoltHi_MFOP
              IN_NePMDR_Cnt_HBSpareSysVoltLow_MFOP_Rx_NePMDR_Cnt_HBSpareSysVoltLow_MFOP: accessed-variable=NePMDR_Cnt_HBSpareSysVoltLow_MFOP_Rx.NePMDR_Cnt_HBSpareSysVoltLow_MFOP
              IN_NePMDR_Cnt_HBSysVoltLow_MFOP_Rx_NePMDR_Cnt_HBSysVoltLow_MFOP: accessed-variable=NePMDR_Cnt_HBSysVoltLow_MFOP_Rx.NePMDR_Cnt_HBSysVoltLow_MFOP
          data-send-points:
            49 x access:
              OUT_VePMDR_b_PTRunAbrt_Value: accessed-variable=VePMDR_b_PTRunAbrt.Value
              OUT_VePMDR_b_RunCrnkActvECM_FA_Value: accessed-variable=VePMDR_b_RunCrnkActvECM_FA.Value
              OUT_VePMDR_U_IgnRunCrnk_Value: accessed-variable=VePMDR_U_IgnRunCrnk.Value
              OUT_VePMDR_b_KeyInIgnFA_Value: accessed-variable=VePMDR_b_KeyInIgnFA.Value
              OUT_VePMDR_b_BCMWakeupLine_Value: accessed-variable=VePMDR_b_BCMWakeupLine.Value
              OUT_VePMDR_b_BCMWakeupLineFA_Value: accessed-variable=VePMDR_b_BCMWakeupLineFA.Value
              OUT_VePMDR_U_HB_SysVolt_Value: accessed-variable=VePMDR_U_HB_SysVolt.Value
              OUT_VePMDR_b_RunCrnkActvECM_Value: accessed-variable=VePMDR_b_RunCrnkActvECM.Value
              OUT_VePMDR_U_BF2_SysVolt_Value: accessed-variable=VePMDR_U_BF2_SysVolt.Value
              OUT_VePMDR_b_OBCMWup_Value: accessed-variable=VePMDR_b_OBCMWup.Value
              OUT_VePMDR_b_OBCMWupFA_Value: accessed-variable=VePMDR_b_OBCMWupFA.Value
              OUT_VePMDR_U_BF1_SysVolt_Value: accessed-variable=VePMDR_U_BF1_SysVolt.Value
              OUT_VePMDR_b_OperationalModeStsFA_Value: accessed-variable=VePMDR_b_OperationalModeStsFA.Value
              OUT_VePMDR_U_BF3_SysVolt_Value: accessed-variable=VePMDR_U_BF3_SysVolt.Value
              OUT_VePMDR_U_HBSpare_SysVolt_Value: accessed-variable=VePMDR_U_HBSpare_SysVolt.Value
              OUT_VePMDR_e_OperationalModeSts_Value: accessed-variable=VePMDR_e_OperationalModeSts.Value
              OUT_VePMDR_b_CrankAborted_Value: accessed-variable=VePMDR_b_CrankAborted.Value
              OUT_VePMDR_U_MainRelay_SysVolt_Value: accessed-variable=VePMDR_U_MainRelay_SysVolt.Value
              OUT_VePMDR_e_KeyInIgn_Value: accessed-variable=VePMDR_e_KeyInIgn.Value
              OUT_VePMDR_b_EStop_Value: accessed-variable=VePMDR_b_EStop.Value
              OUT_VePMDR_b_IgnRunCrnk_Value: accessed-variable=VePMDR_b_IgnRunCrnk.Value
              OUT_VePMDR_b_RunCrankActiveAnalog_Value: accessed-variable=VePMDR_b_RunCrankActiveAnalog.Value
              OUT_VePMDR_e_PMM_PowerMode_Value: accessed-variable=VePMDR_e_PMM_PowerMode.Value
              OUT_VePMDR_t_RunCrankActive_Value: accessed-variable=VePMDR_t_RunCrankActive.Value
              OUT_VePMDR_b_RunCrankActive_Value: accessed-variable=VePMDR_b_RunCrankActive.Value
              OUT_VePMDR_b_SysVoltLowFA_Value: accessed-variable=VePMDR_b_SysVoltLowFA.Value
              OUT_VePMDR_b_SysVoltHighFA_Value: accessed-variable=VePMDR_b_SysVoltHighFA.Value
              OUT_VePMDR_b_StrtCntrlStOn_Value: accessed-variable=VePMDR_b_StrtCntrlStOn.Value
              OUT_VePMDR_b_PMM_PowerModeFA_Value: accessed-variable=VePMDR_b_PMM_PowerModeFA.Value
              OUT_VePMDR_e_IgnInputsPowerMode_Value: accessed-variable=VePMDR_e_IgnInputsPowerMode.Value
              OUT_VePMDR_b_AccRunActiveAnalog_Value: accessed-variable=VePMDR_b_AccRunActiveAnalog.Value
              OUT_VePMDR_b_HB_SysVoltFA_Value: accessed-variable=VePMDR_b_HB_SysVoltFA.Value
              OUT_VePMDR_e_KeyStatus_Value: accessed-variable=VePMDR_e_KeyStatus.Value
              OUT_VePMDR_e_PowerModeRaw_Value: accessed-variable=VePMDR_e_PowerModeRaw.Value
              OUT_VePMDR_b_PowerModeRawFA_Value: accessed-variable=VePMDR_b_PowerModeRawFA.Value
              OUT_VePMDR_b_SysVoltLowFA_BF1_Value: accessed-variable=VePMDR_b_SysVoltLowFA_BF1.Value
              OUT_VePMDR_b_SysVoltLowFA_BF2_Value: accessed-variable=VePMDR_b_SysVoltLowFA_BF2.Value
              OUT_VePMDR_b_SysVoltLowFA_HB_Value: accessed-variable=VePMDR_b_SysVoltLowFA_HB.Value
              OUT_VePMDR_b_SysVoltLowFA_HBSpare_Value: accessed-variable=VePMDR_b_SysVoltLowFA_HBSpare.Value
              OUT_VePMDR_b_SysVoltLowFA_BF3_Value: accessed-variable=VePMDR_b_SysVoltLowFA_BF3.Value
              OUT_VePMDR_b_EngineOffRequest_Value: accessed-variable=VePMDR_b_EngineOffRequest.Value
              OUT_VePMDR_e_FaultSts_SysVoltHi_Value: accessed-variable=VePMDR_e_FaultSts_SysVoltHi.Value
              OUT_VePMDR_e_FaultSts_SysVoltLo_Value: accessed-variable=VePMDR_e_FaultSts_SysVoltLo.Value
              OUT_VePMDR_e_FaultSts_IgnSwAccPstnCktHi_Value: accessed-variable=VePMDR_e_FaultSts_IgnSwAccPstnCktHi.Value
              OUT_VePMDR_e_FaultSts_IgnSwAccPstnCktLo_Value: accessed-variable=VePMDR_e_FaultSts_IgnSwAccPstnCktLo.Value
              OUT_VePMDR_e_FaultSts_IgnSwRunCrnkPstnCktLo_Value: accessed-variable=VePMDR_e_FaultSts_IgnSwRunCrnkPstnCktLo.Value
              OUT_VePMDR_e_FaultSts_IgnSwRunCrnkPstnCktHi_Value: accessed-variable=VePMDR_e_FaultSts_IgnSwRunCrnkPstnCktHi.Value
              OUT_VePMDR_e_FaultSts_IgnSwRunPstnCktHi_Value: accessed-variable=VePMDR_e_FaultSts_IgnSwRunPstnCktHi.Value
              OUT_VePMDR_e_FaultSts_IgnSwRunPstnCktLo_Value: accessed-variable=VePMDR_e_FaultSts_IgnSwRunPstnCktLo.Value
          written-local-variables:
            22 x access:
              WV_VePMDR_b_PowerModeRawFA_write_IRV: accessed-variable=VePMDR_b_PowerModeRawFA_write_IRV
              WV_VePMDR_b_RunCrnkActvECMFA_write_IRV: accessed-variable=VePMDR_b_RunCrnkActvECMFA_write_IRV
              WV_VePMDI_e_PowerModeRaw_write_IRV: accessed-variable=VePMDI_e_PowerModeRaw_write_IRV
              WV_VePMDR_U_BF3_SysVolt_write_IRV: accessed-variable=VePMDR_U_BF3_SysVolt_write_IRV
              WV_VePMDR_U_HBSpare_SysVolt_write_IRV: accessed-variable=VePMDR_U_HBSpare_SysVolt_write_IRV
              WV_VePMDR_b_AccRunActiveAnalog_write_IRV: accessed-variable=VePMDR_b_AccRunActiveAnalog_write_IRV
              WV_VePMDR_b_EngOffRq_C2FA_write_IRV: accessed-variable=VePMDR_b_EngOffRq_C2FA_write_IRV
              WV_VePMDR_b_EngOffReq_C2_Init_write_IRV: accessed-variable=VePMDR_b_EngOffReq_C2_Init_write_IRV
              WV_VePMDR_b_EngOffRq_CFA_write_IRV: accessed-variable=VePMDR_b_EngOffRq_CFA_write_IRV
              WV_VePMDR_b_EngOffReq_C_Init_write_IRV: accessed-variable=VePMDR_b_EngOffReq_C_Init_write_IRV
              WV_VePMDR_b_PAD_Actv_Init_write_IRV: accessed-variable=VePMDR_b_PAD_Actv_Init_write_IRV
              WV_VePMDR_b_PAD_ActvFA_write_IRV: accessed-variable=VePMDR_b_PAD_ActvFA_write_IRV
              WV_VePMDR_b_PMM_PowerModeFA_write_IRV: accessed-variable=VePMDR_b_PMM_PowerModeFA_write_IRV
              WV_VePMDR_b_PowerModeRawFA_write1_IRV: accessed-variable=VePMDR_b_PowerModeRawFA_write1_IRV
              WV_VePMDR_b_RunCrankActiveAnalog_write_IRV: accessed-variable=VePMDR_b_RunCrankActiveAnalog_write_IRV
              WV_VePMDR_b_RunCrankActive_write_IRV: accessed-variable=VePMDR_b_RunCrankActive_write_IRV
              WV_VePMDR_b_RunCrnkActvECM_write_IRV: accessed-variable=VePMDR_b_RunCrnkActvECM_write_IRV
              WV_VePMDR_b_StrtCntrlStOn_ECM_write_IRV: accessed-variable=VePMDR_b_StrtCntrlStOn_ECM_write_IRV
              WV_VePMDR_b_Tonale_PowerModeRawFA_write_IRV: accessed-variable=VePMDR_b_Tonale_PowerModeRawFA_write_IRV
              WV_VePMDR_e_PMM_PowerMode_write_IRV: accessed-variable=VePMDR_e_PMM_PowerMode_write_IRV
              WV_VePMDR_e_PowerModeRaw_write_IRV: accessed-variable=VePMDR_e_PowerModeRaw_write_IRV
              WV_VePMDR_e_Tonale_PowerModeRaw_write_IRV: accessed-variable=VePMDR_e_Tonale_PowerModeRaw_write_IRV
        PMDR_MedTEB
          data-receive-point-by-arguments:
            9 x access:
              IN_VeHPMR_b_PropSysActv_Value: accessed-variable=VeHPMR_b_PropSysActv.Value, variation-point={short-label=vpIN_VeHPMR_b_PropSysActv_Value, sw-syscond=1}
              IN_VePMDB_U_IgnAccRun_Value: accessed-variable=VePMDB_U_IgnAccRun.Value
              IN_VePMDB_U_IgnRunCrnk_Value: accessed-variable=VePMDB_U_IgnRunCrnk.Value
              IN_VePMDB_b_EStop_Value: accessed-variable=VePMDB_b_EStop.Value
              IN_VePMDB_b_IgnAccRun_Value: accessed-variable=VePMDB_b_IgnAccRun.Value
              IN_VePMDB_b_IgnAccRunFA_Value: accessed-variable=VePMDB_b_IgnAccRunFA.Value
              IN_VePMDB_b_IgnRunCrnk_Value: accessed-variable=VePMDB_b_IgnRunCrnk.Value
              IN_VePMDB_b_IgnRunCrnkFA_Value: accessed-variable=VePMDB_b_IgnRunCrnkFA.Value
              IN_VePMDB_b_OBCMWup_Value: accessed-variable=VePMDB_b_OBCMWup.Value
          data-send-points:
            17 x access:
              OUT_VePMDR_e_PowerModeRaw_Value: accessed-variable=VePMDR_e_PowerModeRaw.Value
              OUT_VePMDR_b_PowerModeRawFA_Value: accessed-variable=VePMDR_b_PowerModeRawFA.Value
              OUT_VePMDR_b_AccRunActiveAnalog_Value: accessed-variable=VePMDR_b_AccRunActiveAnalog.Value
              OUT_VePMDR_b_RunCrankActive_Value: accessed-variable=VePMDR_b_RunCrankActive.Value
              OUT_VePMDR_b_RunCrankActiveAnalog_Value: accessed-variable=VePMDR_b_RunCrankActiveAnalog.Value
              OUT_VePMDR_t_RunCrankActive_Value: accessed-variable=VePMDR_t_RunCrankActive.Value
              OUT_VePMDR_e_IgnInputsPowerMode_Value: accessed-variable=VePMDR_e_IgnInputsPowerMode.Value
              OUT_VePMDR_e_PMM_PowerMode_Value: accessed-variable=VePMDR_e_PMM_PowerMode.Value
              OUT_VePMDR_b_PMM_PowerModeFA_Value: accessed-variable=VePMDR_b_PMM_PowerModeFA.Value
              OUT_VePMDR_e_KeyStatus_Value: accessed-variable=VePMDR_e_KeyStatus.Value
              OUT_VePMDR_b_StrtCntrlStOn_Value: accessed-variable=VePMDR_b_StrtCntrlStOn.Value
              OUT_VePMDR_b_EngineOffRequest_Value: accessed-variable=VePMDR_b_EngineOffRequest.Value
              OUT_VePMDR_b_IgnRunCrnk_Value: accessed-variable=VePMDR_b_IgnRunCrnk.Value
              OUT_VePMDR_b_EStop_Value: accessed-variable=VePMDR_b_EStop.Value
              OUT_VePMDR_U_IgnRunCrnk_Value: accessed-variable=VePMDR_U_IgnRunCrnk.Value
              OUT_VePMDR_b_OBCMWup_Value: accessed-variable=VePMDR_b_OBCMWup.Value
              OUT_VePMDR_b_OBCMWupFA_Value: accessed-variable=VePMDR_b_OBCMWupFA.Value
          read-local-variables:
            9 x access:
              RV_VePMDR_b_EngOffReq_C2_Init_write_IRV: accessed-variable=VePMDR_b_EngOffReq_C2_Init_write_IRV
              RV_VePMDR_b_EngOffReq_C_Init_write_IRV: accessed-variable=VePMDR_b_EngOffReq_C_Init_write_IRV
              RV_VePMDR_b_EngOffRq_C2FA_write_IRV: accessed-variable=VePMDR_b_EngOffRq_C2FA_write_IRV
              RV_VePMDR_b_EngOffRq_CFA_write_IRV: accessed-variable=VePMDR_b_EngOffRq_CFA_write_IRV
              RV_VePMDR_b_PowerModeRawFA_write_IRV: accessed-variable=VePMDR_b_PowerModeRawFA_write_IRV
              RV_VePMDR_b_StrtCntrlStOn_ECM_write_IRV: accessed-variable=VePMDR_b_StrtCntrlStOn_ECM_write_IRV
              RV_VePMDR_b_Tonale_PowerModeRawFA_write_IRV: accessed-variable=VePMDR_b_Tonale_PowerModeRawFA_write_IRV
              RV_VePMDR_e_PowerModeRaw_write_IRV: accessed-variable=VePMDR_e_PowerModeRaw_write_IRV
              RV_VePMDR_e_Tonale_PowerModeRaw_write_IRV: accessed-variable=VePMDR_e_Tonale_PowerModeRaw_write_IRV
          written-local-variables:
            7 x access:
              WV_VePMDI_e_PowerModeRaw_write_IRV: accessed-variable=VePMDI_e_PowerModeRaw_write_IRV
              WV_VePMDR_b_AccRunActiveAnalog_write_IRV: accessed-variable=VePMDR_b_AccRunActiveAnalog_write_IRV
              WV_VePMDR_b_PMM_PowerModeFA_write_IRV: accessed-variable=VePMDR_b_PMM_PowerModeFA_write_IRV
              WV_VePMDR_b_PowerModeRawFA_write1_IRV: accessed-variable=VePMDR_b_PowerModeRawFA_write1_IRV
              WV_VePMDR_b_RunCrankActiveAnalog_write_IRV: accessed-variable=VePMDR_b_RunCrankActiveAnalog_write_IRV
              WV_VePMDR_b_RunCrankActive_write_IRV: accessed-variable=VePMDR_b_RunCrankActive_write_IRV
              WV_VePMDR_e_PMM_PowerMode_write_IRV: accessed-variable=VePMDR_e_PMM_PowerMode_write_IRV
        PMDR_MedTEB1
        PMDR_MedTED
          data-receive-point-by-arguments:
            14 x access:
              IN_VeDFIR_b_DiagSystemDsbl_Value: accessed-variable=VeDFIR_b_DiagSystemDsbl.Value
              IN_VeDFIR_b_DsblDiagFailSafe_Value: accessed-variable=VeDFIR_b_DsblDiagFailSafe.Value, variation-point={short-label=vpIN_VeDFIR_b_DsblDiagFailSafe_Value, sw-syscond=1}
              IN_VeDFIR_b_IsDiagGlobalConditionsValid_Value: accessed-variable=VeDFIR_b_IsDiagGlobalConditionsValid.Value, variation-point={short-label=vpIN_VeDFIR_b_IsDiagGlobalConditionsValid_Value, sw-syscond=1}
              IN_VeDFIR_b_PostCodeClrDiagDsbl_Value: accessed-variable=VeDFIR_b_PostCodeClrDiagDsbl.Value, variation-point={short-label=vpIN_VeDFIR_b_PostCodeClrDiagDsbl_Value, sw-syscond=1}
              IN_VeDMAB_y_StatusByte_IgnSwRunCrnkPstnCktHi_Value: accessed-variable=VeDMAB_y_StatusByte_IgnSwRunCrnkPstnCktHi.Value, variation-point={short-label=vpIN_VeDMAB_y_StatusByte_IgnSwRunCrnkPstnCktHi_Value, sw-syscond=1}
              IN_VeDMAB_y_StatusByte_IgnSwRunCrnkPstnCktLo_Value: accessed-variable=VeDMAB_y_StatusByte_IgnSwRunCrnkPstnCktLo.Value, variation-point={short-label=vpIN_VeDMAB_y_StatusByte_IgnSwRunCrnkPstnCktLo_Value, sw-syscond=1}
              IN_VeDMAB_y_StatusByte_IgnSwRunPstnCktHi_Value: accessed-variable=VeDMAB_y_StatusByte_IgnSwRunPstnCktHi.Value, variation-point={short-label=vpIN_VeDMAB_y_StatusByte_IgnSwRunPstnCktHi_Value, sw-syscond=1}
              IN_VeDMAB_y_StatusByte_IgnSwRunPstnCktLo_Value: accessed-variable=VeDMAB_y_StatusByte_IgnSwRunPstnCktLo.Value, variation-point={short-label=vpIN_VeDMAB_y_StatusByte_IgnSwRunPstnCktLo_Value, sw-syscond=1}
              IN_VeDMAB_y_StatusByte_SysVoltHi_Value: accessed-variable=VeDMAB_y_StatusByte_SysVoltHi.Value, variation-point={short-label=vpIN_VeDMAB_y_StatusByte_SysVoltHi_Value, sw-syscond=1}
              IN_VeDMAB_y_StatusByte_SysVoltLo_Value: accessed-variable=VeDMAB_y_StatusByte_SysVoltLo.Value, variation-point={short-label=vpIN_VeDMAB_y_StatusByte_SysVoltLo_Value, sw-syscond=1}
              IN_VeESSR_e_EngStrtType_Value: accessed-variable=VeESSR_e_EngStrtType.Value
              IN_VePMDB_U_BF1_SysVolt_Value: accessed-variable=VePMDB_U_BF1_SysVolt.Value
              IN_VePMDB_U_BF2_SysVolt_Value: accessed-variable=VePMDB_U_BF2_SysVolt.Value
              IN_VePMDB_U_HB_SysVolt_Value: accessed-variable=VePMDB_U_HB_SysVolt.Value
          data-send-points:
            19 x access:
              OUT_VePMDR_b_SysVoltLowFA_Value: accessed-variable=VePMDR_b_SysVoltLowFA.Value
              OUT_VePMDR_b_SysVoltHighFA_Value: accessed-variable=VePMDR_b_SysVoltHighFA.Value
              OUT_VePMDR_b_HB_SysVoltFA_Value: accessed-variable=VePMDR_b_HB_SysVoltFA.Value
              OUT_VePMDR_b_SysVoltLowFA_BF1_Value: accessed-variable=VePMDR_b_SysVoltLowFA_BF1.Value
              OUT_VePMDR_b_SysVoltLowFA_BF2_Value: accessed-variable=VePMDR_b_SysVoltLowFA_BF2.Value
              OUT_VePMDR_b_SysVoltLowFA_HB_Value: accessed-variable=VePMDR_b_SysVoltLowFA_HB.Value
              OUT_VePMDR_b_SysVoltLowFA_HBSpare_Value: accessed-variable=VePMDR_b_SysVoltLowFA_HBSpare.Value
              OUT_VePMDR_b_SysVoltLowFA_BF3_Value: accessed-variable=VePMDR_b_SysVoltLowFA_BF3.Value
              OUT_VePMDR_e_FaultSts_SysVoltHi_Value: accessed-variable=VePMDR_e_FaultSts_SysVoltHi.Value
              OUT_VePMDR_e_FaultSts_SysVoltLo_Value: accessed-variable=VePMDR_e_FaultSts_SysVoltLo.Value
              OUT_VePMDR_e_FaultSts_IgnSwAccPstnCktHi_Value: accessed-variable=VePMDR_e_FaultSts_IgnSwAccPstnCktHi.Value
              OUT_VePMDR_e_FaultSts_IgnSwAccPstnCktLo_Value: accessed-variable=VePMDR_e_FaultSts_IgnSwAccPstnCktLo.Value
              OUT_VePMDR_e_FaultSts_IgnSwRunCrnkPstnCktLo_Value: accessed-variable=VePMDR_e_FaultSts_IgnSwRunCrnkPstnCktLo.Value
              OUT_VePMDR_e_FaultSts_IgnSwRunCrnkPstnCktHi_Value: accessed-variable=VePMDR_e_FaultSts_IgnSwRunCrnkPstnCktHi.Value
              OUT_VePMDR_e_FaultSts_IgnSwRunPstnCktHi_Value: accessed-variable=VePMDR_e_FaultSts_IgnSwRunPstnCktHi.Value
              OUT_VePMDR_e_FaultSts_IgnSwRunPstnCktLo_Value: accessed-variable=VePMDR_e_FaultSts_IgnSwRunPstnCktLo.Value
              OUT_VePMDR_U_BF2_SysVolt_Value: accessed-variable=VePMDR_U_BF2_SysVolt.Value
              OUT_VePMDR_U_BF1_SysVolt_Value: accessed-variable=VePMDR_U_BF1_SysVolt.Value
              OUT_VePMDR_U_HB_SysVolt_Value: accessed-variable=VePMDR_U_HB_SysVolt.Value
          read-local-variables:
            9 x access:
              RV_VePMDI_e_PowerModeRaw_write_IRV: accessed-variable=VePMDI_e_PowerModeRaw_write_IRV, variation-point={short-label=vpRV_VePMDI_e_PowerModeRaw_write_IRV, sw-syscond=1}
              RV_VePMDR_b_AccRunActiveAnalog_write_IRV: accessed-variable=VePMDR_b_AccRunActiveAnalog_write_IRV, variation-point={short-label=vpRV_VePMDR_b_AccRunActiveAnalog_write_IRV, sw-syscond=1}
              RV_VePMDR_b_PMM_PowerModeFA_write_IRV: accessed-variable=VePMDR_b_PMM_PowerModeFA_write_IRV, variation-point={short-label=vpRV_VePMDR_b_PMM_PowerModeFA_write_IRV, sw-syscond=1}
              RV_VePMDR_b_PowerModeRawFA_write1_IRV: accessed-variable=VePMDR_b_PowerModeRawFA_write1_IRV, variation-point={short-label=vpRV_VePMDR_b_PowerModeRawFA_write1_IRV, sw-syscond=1}
              RV_VePMDR_b_RunCrankActiveAnalog_write_IRV: accessed-variable=VePMDR_b_RunCrankActiveAnalog_write_IRV, variation-point={short-label=vpRV_VePMDR_b_RunCrankActiveAnalog_write_IRV, sw-syscond=1}
              RV_VePMDR_b_RunCrankActive_write_IRV: accessed-variable=VePMDR_b_RunCrankActive_write_IRV
              RV_VePMDR_b_RunCrnkActvECMFA_write_IRV: accessed-variable=VePMDR_b_RunCrnkActvECMFA_write_IRV, variation-point={short-label=vpRV_VePMDR_b_RunCrnkActvECMFA_write_IRV, sw-syscond=1}
              RV_VePMDR_b_RunCrnkActvECM_write_IRV: accessed-variable=VePMDR_b_RunCrnkActvECM_write_IRV, variation-point={short-label=vpRV_VePMDR_b_RunCrnkActvECM_write_IRV, sw-syscond=1}
              RV_VePMDR_e_PMM_PowerMode_write_IRV: accessed-variable=VePMDR_e_PMM_PowerMode_write_IRV
        PMDR_PwrOff
          data-send-points:
            16 x access:
              OUT_NePMDD_Cnt_RunCrankOpenMaxFOP_NePMDD_Cnt_RunCrankOpenMaxFOP: accessed-variable=NePMDD_Cnt_RunCrankOpenMaxFOP.NePMDD_Cnt_RunCrankOpenMaxFOP
              OUT_NePMDD_Cnt_RunCrankHiMaxFOP_NePMDD_Cnt_RunCrankHiMaxFOP: accessed-variable=NePMDD_Cnt_RunCrankHiMaxFOP.NePMDD_Cnt_RunCrankHiMaxFOP
              OUT_NePMDD_Cnt_AccLoMaxFOP_NePMDD_Cnt_AccLoMaxFOP: accessed-variable=NePMDD_Cnt_AccLoMaxFOP.NePMDD_Cnt_AccLoMaxFOP
              OUT_NePMDD_Cnt_AccHiMaxFOP_NePMDD_Cnt_AccHiMaxFOP: accessed-variable=NePMDD_Cnt_AccHiMaxFOP.NePMDD_Cnt_AccHiMaxFOP
              OUT_NePMDD_Cnt_RunLoMaxFOP_NePMDD_Cnt_RunLoMaxFOP: accessed-variable=NePMDD_Cnt_RunLoMaxFOP.NePMDD_Cnt_RunLoMaxFOP
              OUT_NePMDD_Cnt_RunHiMaxFOP_NePMDD_Cnt_RunHiMaxFOP: accessed-variable=NePMDD_Cnt_RunHiMaxFOP.NePMDD_Cnt_RunHiMaxFOP
              OUT_NePMDR_Cnt_BF1SysVoltHi_MFOP_NePMDR_Cnt_BF1SysVoltHi_MFOP: accessed-variable=NePMDR_Cnt_BF1SysVoltHi_MFOP.NePMDR_Cnt_BF1SysVoltHi_MFOP
              OUT_NePMDR_Cnt_BF1SysVoltLow_MFOP_NePMDR_Cnt_BF1SysVoltLow_MFOP: accessed-variable=NePMDR_Cnt_BF1SysVoltLow_MFOP.NePMDR_Cnt_BF1SysVoltLow_MFOP
              OUT_NePMDR_Cnt_BF2SysVoltHi_MFOP_NePMDR_Cnt_BF2SysVoltHi_MFOP: accessed-variable=NePMDR_Cnt_BF2SysVoltHi_MFOP.NePMDR_Cnt_BF2SysVoltHi_MFOP
              OUT_NePMDR_Cnt_BF2SysVoltLow_MFOP_NePMDR_Cnt_BF2SysVoltLow_MFOP: accessed-variable=NePMDR_Cnt_BF2SysVoltLow_MFOP.NePMDR_Cnt_BF2SysVoltLow_MFOP
              OUT_NePMDR_Cnt_BF3SysVoltHi_MFOP_NePMDR_Cnt_BF3SysVoltHi_MFOP: accessed-variable=NePMDR_Cnt_BF3SysVoltHi_MFOP.NePMDR_Cnt_BF3SysVoltHi_MFOP
              OUT_NePMDR_Cnt_BF3SysVoltLow_MFOP_NePMDR_Cnt_BF3SysVoltLow_MFOP: accessed-variable=NePMDR_Cnt_BF3SysVoltLow_MFOP.NePMDR_Cnt_BF3SysVoltLow_MFOP
              OUT_NePMDR_Cnt_BFHBSpareSysVoltHi_MFOP_NePMDR_Cnt_BFHBSpareSysVoltHi_MFOP: accessed-variable=NePMDR_Cnt_BFHBSpareSysVoltHi_MFOP.NePMDR_Cnt_BFHBSpareSysVoltHi_MFOP
              OUT_NePMDR_Cnt_BFHBSysVoltHi_MFOP_NePMDR_Cnt_BFHBSysVoltHi_MFOP: accessed-variable=NePMDR_Cnt_BFHBSysVoltHi_MFOP.NePMDR_Cnt_BFHBSysVoltHi_MFOP
              OUT_NePMDR_Cnt_HBSpareSysVoltLow_MFOP_NePMDR_Cnt_HBSpareSysVoltLow_MFOP: accessed-variable=NePMDR_Cnt_HBSpareSysVoltLow_MFOP.NePMDR_Cnt_HBSpareSysVoltLow_MFOP
              OUT_NePMDR_Cnt_HBSysVoltLow_MFOP_NePMDR_Cnt_HBSysVoltLow_MFOP: accessed-variable=NePMDR_Cnt_HBSysVoltLow_MFOP.NePMDR_Cnt_HBSysVoltLow_MFOP
        FsftPMDR_b_EngOffRq_C
          written-local-variables:
            access WV_VePMDR_b_EngOffRq_CFA_write_IRV: accessed-variable=VePMDR_b_EngOffRq_CFA_write_IRV
        FsftPMDR_b_EngOffRq_C2
          written-local-variables:
            access WV_VePMDR_b_EngOffRq_C2FA_write_IRV: accessed-variable=VePMDR_b_EngOffRq_C2FA_write_IRV
        FsftPMDR_b_OperationalModeSts
          data-send-points:
            access OUT_VePMDR_b_OperationalModeStsFA_Value: accessed-variable=VePMDR_b_OperationalModeStsFA.Value
        FsftPMDR_b_PAD_Actv
        FsftPMDR_b_RunCrnkActvECM
          data-send-points:
            access OUT_VePMDR_b_RunCrnkActvECM_FA_Value: accessed-variable=VePMDR_b_RunCrnkActvECM_FA.Value
          written-local-variables:
            access WV_VePMDR_b_RunCrnkActvECMFA_write_IRV: accessed-variable=VePMDR_b_RunCrnkActvECMFA_write_IRV
        FsftPMDR_b_StrtCntrlStOn
        FsftPMDR_e_KeyInIgn
          data-send-points:
            access OUT_VePMDR_b_KeyInIgnFA_Value: accessed-variable=VePMDR_b_KeyInIgnFA.Value
        FsftPMDR_e_PowerModeRaw
          written-local-variables:
            access WV_VePMDR_b_PowerModeRawFA_write_IRV: accessed-variable=VePMDR_b_PowerModeRawFA_write_IRV
        FsftPMDR_e_Tonale_PowerModeRaw
          written-local-variables:
            access WV_VePMDR_b_Tonale_PowerModeRawFA_write_IRV: accessed-variable=VePMDR_b_Tonale_PowerModeRawFA_write_IRV
        PokePMDR_U_BF3_SysVolt
          data-send-points:
            access OUT_VePMDR_U_BF3_SysVolt_Value: accessed-variable=VePMDR_U_BF3_SysVolt.Value
        PokePMDR_U_HBSpare_SysVolt
          data-send-points:
            access OUT_VePMDR_U_HBSpare_SysVolt_Value: accessed-variable=VePMDR_U_HBSpare_SysVolt.Value
        PokePMDR_U_MainRelay_SysVolt
          data-send-points:
            access OUT_VePMDR_U_MainRelay_SysVolt_Value: accessed-variable=VePMDR_U_MainRelay_SysVolt.Value
        PokePMDR_b_BCMWup
          data-send-points:
            access OUT_VePMDR_b_BCMWakeupLine_Value: accessed-variable=VePMDR_b_BCMWakeupLine.Value
            access OUT_VePMDR_b_BCMWakeupLineFA_Value: accessed-variable=VePMDR_b_BCMWakeupLineFA.Value
        PokePMDR_b_CrankAborted
          data-send-points:
            access OUT_VePMDR_b_CrankAborted_Value: accessed-variable=VePMDR_b_CrankAborted.Value
        PokePMDR_b_EngOffRq_C
          written-local-variables:
            access WV_VePMDR_b_EngOffRq_CFA_write_IRV: accessed-variable=VePMDR_b_EngOffRq_CFA_write_IRV
            access WV_VePMDR_b_EngOffReq_C_Init_write_IRV: accessed-variable=VePMDR_b_EngOffReq_C_Init_write_IRV
        PokePMDR_b_EngOffRq_C2
          written-local-variables:
            access WV_VePMDR_b_EngOffRq_C2FA_write_IRV: accessed-variable=VePMDR_b_EngOffRq_C2FA_write_IRV
            access WV_VePMDR_b_EngOffReq_C2_Init_write_IRV: accessed-variable=VePMDR_b_EngOffReq_C2_Init_write_IRV
        PokePMDR_b_PAD_Actv
        PokePMDR_b_PTRunAbrt
          data-send-points:
            access OUT_VePMDR_b_PTRunAbrt_Value: accessed-variable=VePMDR_b_PTRunAbrt.Value
        PokePMDR_b_RunCrnkActvECM
          data-send-points:
            access OUT_VePMDR_b_RunCrnkActvECM_Value: accessed-variable=VePMDR_b_RunCrnkActvECM.Value
            access OUT_VePMDR_b_RunCrnkActvECM_FA_Value: accessed-variable=VePMDR_b_RunCrnkActvECM_FA.Value
          written-local-variables:
            access WV_VePMDR_b_RunCrnkActvECMFA_write_IRV: accessed-variable=VePMDR_b_RunCrnkActvECMFA_write_IRV
            access WV_VePMDR_b_RunCrnkActvECM_write_IRV: accessed-variable=VePMDR_b_RunCrnkActvECM_write_IRV
        PokePMDR_b_StrtCntrlStOn
          written-local-variables:
            access WV_VePMDR_b_StrtCntrlStOn_ECM_write_IRV: accessed-variable=VePMDR_b_StrtCntrlStOn_ECM_write_IRV
        PokePMDR_e_KeyInIgn
          data-send-points:
            access OUT_VePMDR_e_KeyInIgn_Value: accessed-variable=VePMDR_e_KeyInIgn.Value
            access OUT_VePMDR_b_KeyInIgnFA_Value: accessed-variable=VePMDR_b_KeyInIgnFA.Value
        PokePMDR_e_OperationalModeSts
          data-send-points:
            access OUT_VePMDR_e_OperationalModeSts_Value: accessed-variable=VePMDR_e_OperationalModeSts.Value
            access OUT_VePMDR_b_OperationalModeStsFA_Value: accessed-variable=VePMDR_b_OperationalModeStsFA.Value
        PokePMDR_e_PowerModeRaw
          written-local-variables:
            access WV_VePMDR_b_PowerModeRawFA_write_IRV: accessed-variable=VePMDR_b_PowerModeRawFA_write_IRV
            access WV_VePMDR_e_PowerModeRaw_write_IRV: accessed-variable=VePMDR_e_PowerModeRaw_write_IRV
        PokePMDR_e_Tonale_PowerModeRaw
          written-local-variables:
            access WV_VePMDR_b_Tonale_PowerModeRawFA_write_IRV: accessed-variable=VePMDR_b_Tonale_PowerModeRawFA_write_IRV
            access WV_VePMDR_e_Tonale_PowerModeRaw_write_IRV: accessed-variable=VePMDR_e_Tonale_PowerModeRaw_write_IRV
      10 x variation point proxy, all with category=CONDITION:
        Variant_PMDR_1: condition-access=1
        Variant_PMDR_10: condition-access=0
        Variant_PMDR_11: condition-access=1
        Variant_PMDR_12: condition-access=1
        Variant_PMDR_4: condition-access=1
        Variant_PMDR_5: condition-access=1
        Variant_PMDR_6: condition-access=0
        Variant_PMDR_7: condition-access=1
        Variant_PMDR_8: condition-access=0
        Variant_PMDR_9: condition-access=1
